AUTOSAR XML (schema 00044)
package /E40_Platform_System_SystemPackage/Components
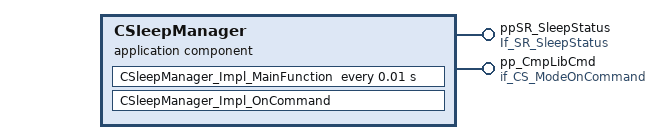
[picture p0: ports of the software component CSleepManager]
  application sw component type CSleepManager
    provide port ppSR_SleepStatus: nonqueued-sender-com-spec{data-element=SleepManager_SleepStatus, init-value=constant-reference=CSleepManagerSleepManager_SleepStatusValue0}, provided-interface=If_SR_SleepStatus
    provide port pp_CmpLibCmd: server-com-spec{operation=Impl_OnCommand, queue-length=1}, provided-interface=if_CS_ModeOnCommand
    behavior IB_CSleepManager
      timing event TECSleepManager_Impl_MainFunction: start-on-event=CSleepManager_Impl_MainFunction, period=0.01
      operation invoked event OIE_pp_CmpLibCmd_CSleepManager_Impl_OnCommandTrigByImpl_OnCommand: start-on-event=CSleepManager_Impl_OnCommand, operation=pp_CmpLibCmd.Impl_OnCommand
      port-api-options:
        enable-take-address=false, indirect-api=false, port=ppSR_SleepStatus
        enable-take-address=false, indirect-api=false, port=pp_CmpLibCmd
      runnable CSleepManager_Impl_MainFunction: can-be-invoked-concurrently=true
        data-send-points:
          access DWA_ppSR_SleepStatus_SleepManager_SleepStatus: accessed-variable=ppSR_SleepStatus.SleepManager_SleepStatus
      runnable CSleepManager_Impl_OnCommand: can-be-invoked-concurrently=true
  swc implementation IMPL_CSleepManager: behavior=IB_CSleepManager
